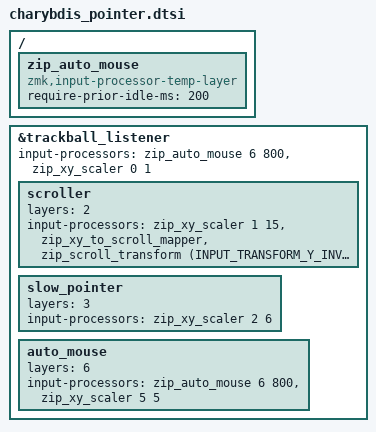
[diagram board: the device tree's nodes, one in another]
#include <input/processors.dtsi>
#include <dt-bindings/zmk/input_transform.h>

/ {
    /* Custom temp-layer processor: won't activate while typing (500ms idle required) */
    zip_auto_mouse: zip_auto_mouse {
        compatible = "zmk,input-processor-temp-layer";
        #input-processor-cells = <2>;
        require-prior-idle-ms = <200>;
    };
};

&trackball_listener {
    /* Base chain: try to activate AUTO_MOUSE layer 6 (suppressed during typing),
       and zero out movement until that layer is active */
    input-processors = <
        &zip_auto_mouse 6 800
        &zip_xy_scaler 0 1
    >;

    /* scroll override — SYM layer; defined first so it takes priority */
    scroller: scroller {
        layers           = <2>;
        input-processors = <
            &zip_xy_scaler 1 15
            &zip_xy_to_scroll_mapper
            &zip_scroll_transform (INPUT_TRANSFORM_Y_INVERT)
        >;
    };

    /* slow-pointer active on SHORTCUTS layer */
    slow_pointer: slow_pointer {
        layers           = <3>;
        input-processors = <&zip_xy_scaler 2 6>;
    };

    /* auto-mouse: normal speed when intentionally using the trackball */
    auto_mouse: auto_mouse {
        layers           = <6>;
        input-processors = <
            &zip_auto_mouse 6 800
            &zip_xy_scaler 5 5
        >;
    };
};
